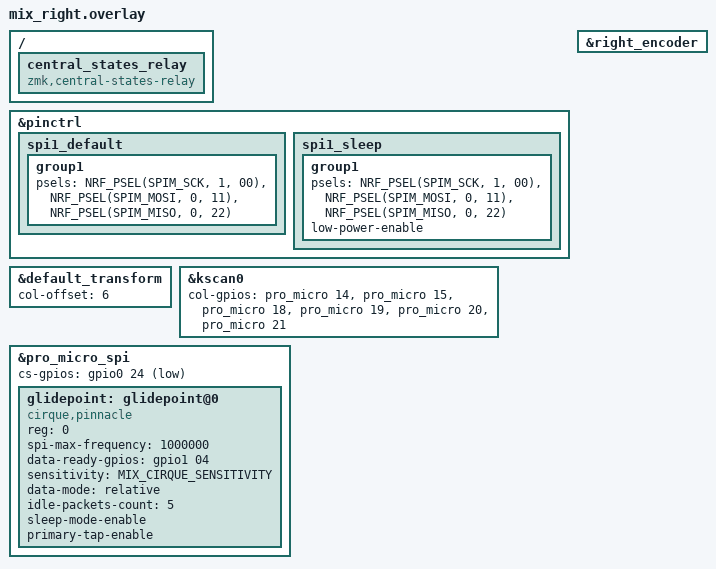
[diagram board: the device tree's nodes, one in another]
/*
 * Copyright (c) 2020 Pete Johanson
 *
 * SPDX-License-Identifier: MIT
 */

#include "mix.dtsi"
#include "../../../config/mix_trackpad_config.dtsi"
#include "mix_trackpad.dtsi"

#include <dt-bindings/zmk/outputs.h>
#include <zephyr/dt-bindings/input/input-event-codes.h>
#include <dt-bindings/zmk/ext_power.h>
#include <dt-bindings/zmk/pointing.h>



&pinctrl {
    /* configuration for spi1 device, default state */
    spi1_default: spi1_default {
        /* node name is arbitrary */
        group1 {
            psels = <NRF_PSEL(SPIM_SCK,  1, 00)>,
                    <NRF_PSEL(SPIM_MOSI, 0, 11)>,
                    <NRF_PSEL(SPIM_MISO, 0, 22)>;
        };
    };

    /* configuration for spi1 device, sleep state */
    spi1_sleep: spi1_sleep {
        group1 {
            psels = <NRF_PSEL(SPIM_SCK, 1, 00)>,
                    <NRF_PSEL(SPIM_MOSI, 0, 11)>,
                    <NRF_PSEL(SPIM_MISO, 0, 22)>;
            low-power-enable;
        };
    };

};




&default_transform {
    col-offset = <6>;
};


&kscan0 {
    col-gpios
        = <&pro_micro 14 GPIO_ACTIVE_HIGH>
        , <&pro_micro 15 GPIO_ACTIVE_HIGH>
        , <&pro_micro 18 GPIO_ACTIVE_HIGH>
        , <&pro_micro 19 GPIO_ACTIVE_HIGH>
        , <&pro_micro 20 GPIO_ACTIVE_HIGH>
        , <&pro_micro 21 GPIO_ACTIVE_HIGH>
        ;
};


&pro_micro_spi {
    status = "okay";
    cs-gpios = <&gpio0 24 GPIO_ACTIVE_LOW>;

    // Upstream Zephyr Cirque Pinnacle driver:
    // https://github.com/zephyrproject-rtos/zephyr/blob/main/drivers/input/input_pinnacle.c
    glidepoint: glidepoint@0 {
        compatible = "cirque,pinnacle";
        reg = <0>;
        spi-max-frequency = <1000000>;
        status = "okay";
        data-ready-gpios = <&gpio1 04 (GPIO_ACTIVE_HIGH)>;

        // ADC sensitivity: "1x", "2x", "3x", "4x" (default "4x")
        sensitivity = MIX_CIRQUE_SENSITIVITY;
        // Data mode: "relative" (default) or "absolute"
        data-mode = "relative";
        // Idle packets count when no touch detected (0-255, default 0)
        idle-packets-count = <5>;
        // Enable trackpad sleep mode after 5 sec without touch
        sleep-mode-enable;
        primary-tap-enable;
    };
};

/ {
    central_states_relay {
        compatible = "zmk,central-states-relay";
    };
};

&right_encoder {
    status = "okay";
};
